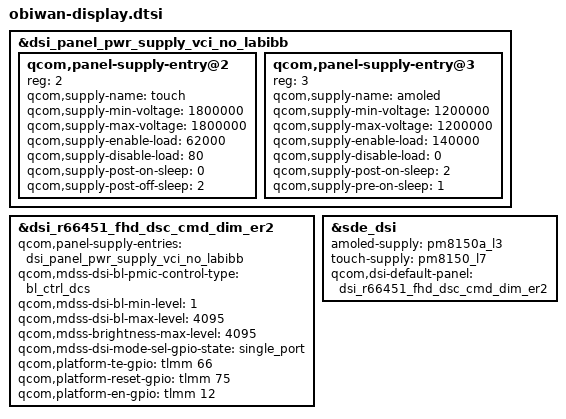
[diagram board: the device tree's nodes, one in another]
/*
 * Copyright (c) 2021 Paranoid Android
 *
 * This program is free software; you can redistribute it and/or modify it
 * under the terms of the GNU General Public License version 2 as published by
 * the Free Software Foundation.
 */

#include "dsi-panel-asus-r66451-fhd-dsc-cmd-dim-er2.dtsi"

&dsi_panel_pwr_supply_vci_no_labibb {
	qcom,panel-supply-entry@2 {
		reg = <2>;
		qcom,supply-name = "touch";
		qcom,supply-min-voltage = <1800000>;
		qcom,supply-max-voltage = <1800000>;
		qcom,supply-enable-load = <62000>;
		qcom,supply-disable-load = <80>;
		qcom,supply-post-on-sleep = <0>;
		qcom,supply-post-off-sleep = <2>;
	};

	qcom,panel-supply-entry@3 {
		reg = <3>;
		qcom,supply-name = "amoled"; // External VDD
		qcom,supply-min-voltage = <1200000>;
		qcom,supply-max-voltage = <1200000>;
		qcom,supply-enable-load = <140000>;
		qcom,supply-disable-load = <0>;
		qcom,supply-post-on-sleep = <2>; // TRW1
		qcom,supply-pre-on-sleep = <1>; // TSVDD
	};
};

&dsi_r66451_fhd_dsc_cmd_dim_er2 {
	qcom,panel-supply-entries = <&dsi_panel_pwr_supply_vci_no_labibb>;
	qcom,mdss-dsi-bl-pmic-control-type = "bl_ctrl_dcs";
	qcom,mdss-dsi-bl-min-level = <1>;
	qcom,mdss-dsi-bl-max-level = <4095>;
	qcom,mdss-brightness-max-level = <4095>;
	qcom,mdss-dsi-mode-sel-gpio-state = "single_port";
	qcom,platform-te-gpio = <&tlmm 66 0>;
	qcom,platform-reset-gpio = <&tlmm 75 0>;
	qcom,platform-en-gpio = <&tlmm 12 0>;
};

&sde_dsi {
	amoled-supply = <&pm8150a_l3>;
	touch-supply = <&pm8150_l7>;
	qcom,dsi-default-panel = <&dsi_r66451_fhd_dsc_cmd_dim_er2>;
};
